# STM32F745 register map
File version: 1.6
CPU: CM7 r0p1, little endian, MPU, FPU, 4 interrupt priority bits
Registers are 32-bit, read-write, reset 0x0 unless marked. A register's access mark holds for its fields unless they carry their own. Offsets are from the block's base; [hi:lo] are bit positions.

## Ethernet_PTP — Ethernet: Precision time protocol
Base 0x40028700
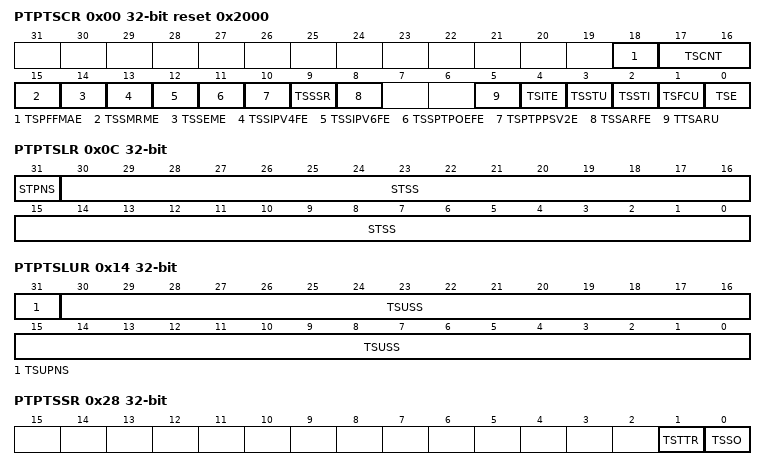
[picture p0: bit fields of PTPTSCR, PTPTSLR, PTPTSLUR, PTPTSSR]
0x00 PTPTSCR reset 0x2000 — Ethernet PTP time stamp control register
  [18] TSPFFMAE, [17:16] TSCNT, [15] TSSMRME, [14] TSSEME, [13] TSSIPV4FE, [12] TSSIPV6FE, [11] TSSPTPOEFE, [10] TSPTPPSV2E, [9] TSSSR, [8] TSSARFE, [5] TTSARU, [4] TSITE, [3] TSSTU, [2] TSSTI, [1] TSFCU, [0] TSE
0x04 PTPSSIR — Ethernet PTP subsecond increment register
  [7:0] STSSI
0x08 PTPTSHR ro — Ethernet PTP time stamp high register
  [31:0] STS
0x0C PTPTSLR ro — Ethernet PTP time stamp low register
  [31] STPNS, [30:0] STSS
0x10 PTPTSHUR — Ethernet PTP time stamp high update register
  [31:0] TSUS
0x14 PTPTSLUR — Ethernet PTP time stamp low update register
  [31] TSUPNS, [30:0] TSUSS
0x18 PTPTSAR — Ethernet PTP time stamp addend register
  [31:0] TSA
0x1C PTPTTHR — Ethernet PTP target time high register
  [31:0] TTSH — 0
0x20 PTPTTLR — Ethernet PTP target time low register
  [31:0] TTSL
0x28 PTPTSSR ro — Ethernet PTP time stamp status register
  [1] TSTTR — TSSO
  [0] TSSO
0x2C PTPPPSCR ro — Ethernet PTP PPS control register
  [3:0] PPSFREQ rw — PPS frequency selection
    0=Hz_1 (1 Hz with a pulse width of 125 ms for binary rollover and of 100 ms for digital rollover); 1=Hz_2 (2 Hz with 50% duty cycle for binary rollover (digital rollover not recommended)); 2=Hz_4 (4 Hz with 50% duty cycle for binary rollover (digital rollover not recommended)); 3=Hz_8 (8 Hz with 50% duty cycle for binary rollover (digital rollover not recommended)); 4=Hz_16 (16 Hz with 50% duty cycle for binary rollover (digital rollover not recommended)); 5=Hz_32 (32 Hz with 50% duty cycle for binary rollover (digital rollover not recommended)); 6=Hz_64 (64 Hz with 50% duty cycle for binary rollover (digital rollover not recommended)); 7=Hz_128 (128 Hz with 50% duty cycle for binary rollover (digital rollover not recommended)); 8=Hz_256 (256 Hz with 50% duty cycle for binary rollover (digital rollover not recommended)); 9=Hz_512 (512 Hz with 50% duty cycle for binary rollover (digital rollover not recommended)); 10=Hz_1024 (1024 Hz with 50% duty cycle for binary rollover (digital rollover not recommended)); 11=Hz_2048 (2048 Hz with 50% duty cycle for binary rollover (digital rollover not recommended)); 12=Hz_4096 (4096 Hz with 50% duty cycle for binary rollover (digital rollover not recommended)); 13=Hz_8192 (8192 Hz with 50% duty cycle for binary rollover (digital rollover not recommended)); 14=Hz_16384 (16384 Hz with 50% duty cycle for binary rollover (digital rollover not recommended)); 15=Hz_32768 (32768 Hz with 50% duty cycle for binary rollover (digital rollover not recommended))

## CRC — Cryptographic processor
Base 0x40023000
0x00 DR reset 0xFFFFFFFF — Data register
  [31:0] DR — Data Register
0x00 DR8 8-bit reset 0xFF (alternate view of DR) — Data register - byte sized
  [7:0] DR8 — Data register bits
0x00 DR16 16-bit reset 0xFFFF (alternate view of DR) — Data register - half-word sized
  [15:0] DR16 — Data register bits
0x04 IDR — Independent Data register
  [7:0] IDR
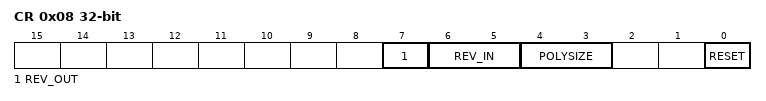
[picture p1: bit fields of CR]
0x08 CR wo — Control register
  [7] REV_OUT rw — Reverse output data
    0=Normal (Bit order not affected); 1=Reversed (Bit reversed output)
  [6:5] REV_IN rw — Reverse input data
    0=Normal (Bit order not affected); 1=Byte (Bit reversal done by byte); 2=HalfWord (Bit reversal done by half-word); 3=Word (Bit reversal done by word)
  [4:3] POLYSIZE rw — Polynomial size
    0=32-bit polynomial; 1=16-bit polynomial; 2=8-bit polynomial; 3=7-bit polynomial
  [0] RESET — RESET bit
    1=Resets the CRC calculation unit and sets the data register to 0xFFFF FFFF
0x10 INIT — Initial CRC value
  [31:0] INIT — Programmable initial CRC value
0x14 POL — CRC polynomial
  [31:0] POL — Programmable polynomial
